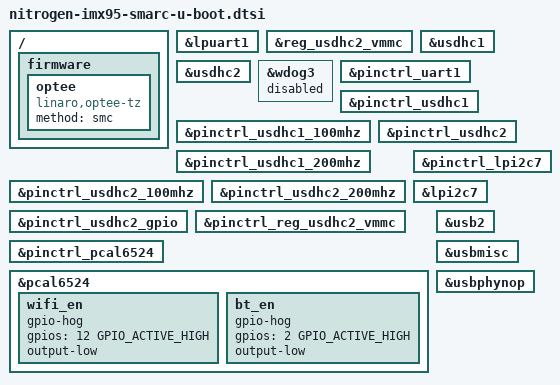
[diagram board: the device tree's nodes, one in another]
// SPDX-License-Identifier: GPL-2.0+
/*
 * Copyright 2025 Ezurio LLC
 */

#include "imx95-u-boot.dtsi"

/ {
	firmware {
		optee {
			compatible = "linaro,optee-tz";
			method = "smc";
		};
	};
};

&lpuart1 {
	bootph-pre-ram;
};

&reg_usdhc2_vmmc {
	bootph-pre-ram;
};

&usdhc1 {
	bootph-pre-ram;
};

&usdhc2 {
	bootph-pre-ram;
};

&wdog3 {
	status = "disabled";
};

&pinctrl_uart1 {
	bootph-pre-ram;
};

&pinctrl_usdhc1 {
	bootph-pre-ram;
};

&pinctrl_usdhc1_100mhz {
	bootph-pre-ram;
};

&pinctrl_usdhc1_200mhz {
	bootph-pre-ram;
};

&pinctrl_usdhc2 {
	bootph-pre-ram;
};

&pinctrl_usdhc2_100mhz {
	bootph-pre-ram;
};

&pinctrl_usdhc2_200mhz {
	bootph-pre-ram;
};

&pinctrl_usdhc2_gpio {
	bootph-pre-ram;
};

&pinctrl_reg_usdhc2_vmmc {
	bootph-pre-ram;
};

&pinctrl_lpi2c7 {
	bootph-all;
};

&pinctrl_pcal6524 {
	bootph-all;
};

&lpi2c7 {
	bootph-all;
};

&pcal6524 {
	bootph-all;

	wifi_en {
		bootph-all;
		gpio-hog;
		gpios = <12 GPIO_ACTIVE_HIGH>;
		output-low;
	};

	bt_en {
		bootph-all;
		gpio-hog;
		gpios = <2 GPIO_ACTIVE_HIGH>;
		output-low;
	};
};

&usb2 {
	bootph-pre-ram;
};

&usbmisc {
	bootph-pre-ram;
};

&usbphynop {
	bootph-pre-ram;
};
